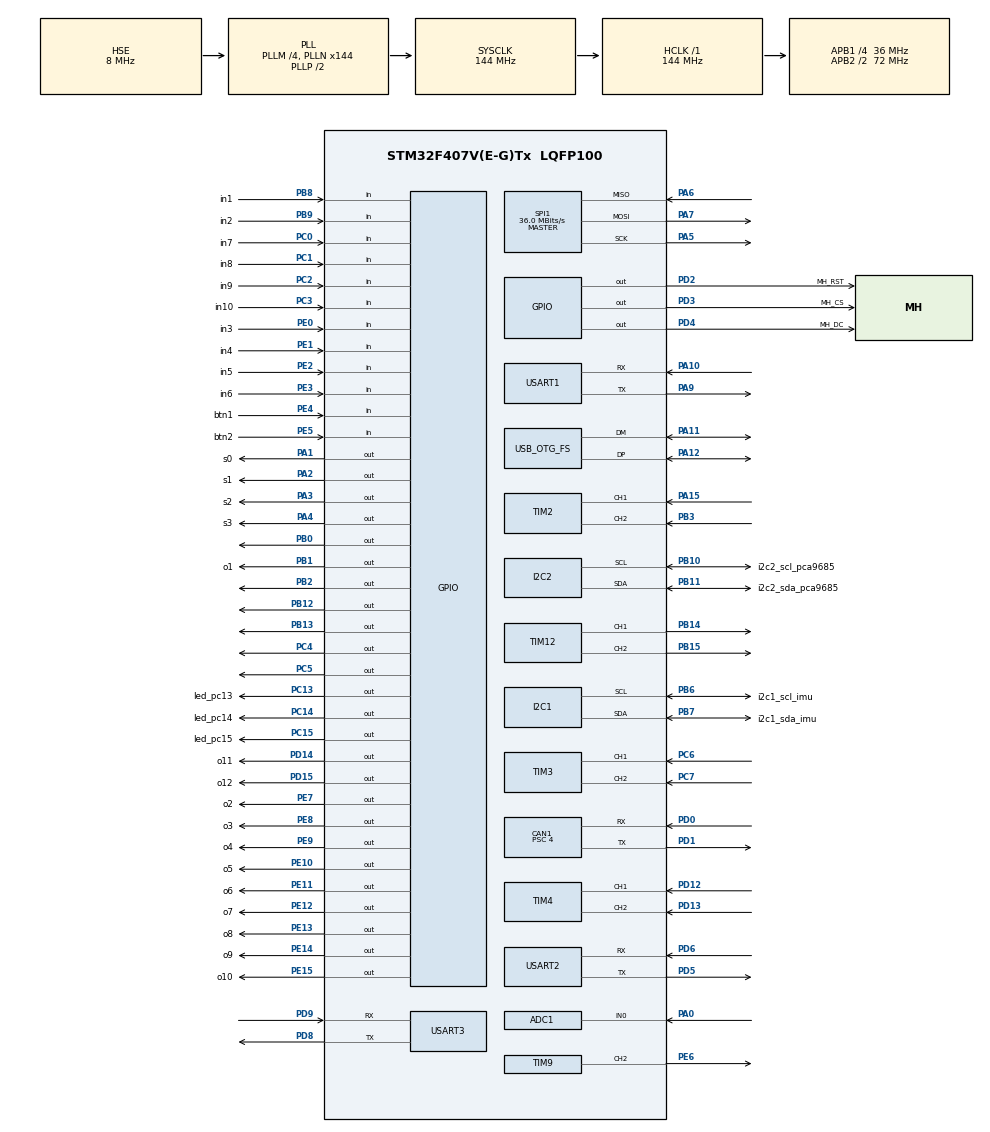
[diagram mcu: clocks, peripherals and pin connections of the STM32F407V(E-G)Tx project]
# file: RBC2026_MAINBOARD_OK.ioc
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ADC1.Channel-0\#ChannelRegularConversion=ADC_CHANNEL_0
ADC1.NbrOfConversionFlag=1
ADC1.Rank-0\#ChannelRegularConversion=1
ADC1.SamplingTime-0\#ChannelRegularConversion=ADC_SAMPLETIME_480CYCLES
ADC1.ScanConvMode=ENABLE
ADC1.master=1
CAN1.ABOM=ENABLE
CAN1.BS1=CAN_BS1_13TQ
CAN1.BS2=CAN_BS2_2TQ
CAN1.CalculateBaudRate=562500
CAN1.CalculateTimeBit=1777
CAN1.CalculateTimeQuantum=111.11111111111111
CAN1.Prescaler=4
Dma.ADC1.0.Direction=DMA_PERIPH_TO_MEMORY
Dma.ADC1.0.FIFOMode=DMA_FIFOMODE_DISABLE
Dma.ADC1.0.Instance=DMA2_Stream0
Dma.ADC1.0.MemDataAlignment=DMA_MDATAALIGN_HALFWORD
Dma.ADC1.0.MemInc=DMA_MINC_ENABLE
Dma.ADC1.0.Mode=DMA_NORMAL
Dma.ADC1.0.PeriphDataAlignment=DMA_PDATAALIGN_HALFWORD
Dma.ADC1.0.PeriphInc=DMA_PINC_DISABLE
Dma.ADC1.0.Priority=DMA_PRIORITY_LOW
Dma.Request0=ADC1
Dma.Request1=USART3_RX
Dma.USART3_RX.1.Direction=DMA_PERIPH_TO_MEMORY
Dma.USART3_RX.1.FIFOMode=DMA_FIFOMODE_DISABLE
Dma.USART3_RX.1.Instance=DMA1_Stream1
Dma.USART3_RX.1.MemDataAlignment=DMA_MDATAALIGN_BYTE
Dma.USART3_RX.1.MemInc=DMA_MINC_ENABLE
Dma.USART3_RX.1.Mode=DMA_NORMAL
Dma.USART3_RX.1.PeriphDataAlignment=DMA_PDATAALIGN_BYTE
Dma.USART3_RX.1.PeriphInc=DMA_PINC_DISABLE
Dma.USART3_RX.1.Priority=DMA_PRIORITY_VERY_HIGH
Mcu.Family=STM32F4
Mcu.Name=STM32F407V(E-G)Tx
Mcu.Package=LQFP100
NVIC.DMA1_Stream1_IRQn=true\:0\:0\:false\:false\:true\:false\:true\:true
NVIC.DMA2_Stream0_IRQn=true\:0\:0\:false\:false\:true\:false\:true\:true
NVIC.OTG_FS_IRQn=true\:0\:0\:false\:false\:true\:false\:true\:true
NVIC.PriorityGroup=NVIC_PRIORITYGROUP_4
NVIC.TIM1_UP_TIM10_IRQn=true\:6\:0\:true\:false\:true\:true\:true\:true
NVIC.TIM8_UP_TIM13_IRQn=true\:7\:0\:true\:false\:true\:true\:true\:true
NVIC.USART3_IRQn=true\:0\:0\:false\:false\:true\:true\:true\:true
PA0-WKUP.Signal=ADCx_IN0
PA1.GPIO_Label=s0
PA1.Signal=GPIO_Output
PA10.Mode=Asynchronous
PA10.Signal=USART1_RX
PA11.Mode=Device_Only
PA11.Signal=USB_OTG_FS_DM
PA12.Mode=Device_Only
PA12.Signal=USB_OTG_FS_DP
PA13.Mode=Serial_Wire
PA13.Signal=SYS_JTMS-SWDIO
PA14.Mode=Serial_Wire
PA14.Signal=SYS_JTCK-SWCLK
PA15.Signal=S_TIM2_CH1_ETR
PA2.GPIO_Label=s1
PA2.Signal=GPIO_Output
PA3.GPIO_Label=s2
PA3.Signal=GPIO_Output
PA4.GPIO_Label=s3
PA4.Signal=GPIO_Output
PA5.Mode=Full_Duplex_Master
PA5.Signal=SPI1_SCK
PA6.Mode=Full_Duplex_Master
PA6.Signal=SPI1_MISO
PA7.Mode=Full_Duplex_Master
PA7.Signal=SPI1_MOSI
PA9.Mode=Asynchronous
PA9.Signal=USART1_TX
PB0.Signal=GPIO_Output
PB1.GPIO_Label=o1
PB1.Signal=GPIO_Output
PB10.GPIO_Label=i2c2_scl_pca9685
PB10.Mode=I2C
PB10.Signal=I2C2_SCL
PB11.GPIO_Label=i2c2_sda_pca9685
PB11.Mode=I2C
PB11.Signal=I2C2_SDA
PB12.Signal=GPIO_Output
PB13.Signal=GPIO_Output
PB14.Signal=S_TIM12_CH1
PB15.Signal=S_TIM12_CH2
PB2.Signal=GPIO_Output
PB3.Signal=S_TIM2_CH2
PB6.GPIO_Label=i2c1_scl_imu
PB6.Mode=I2C
PB6.Signal=I2C1_SCL
PB7.GPIO_Label=i2c1_sda_imu
PB7.Mode=I2C
PB7.Signal=I2C1_SDA
PB8.GPIO_Label=in1
PB8.Signal=GPIO_Input
PB9.GPIO_Label=in2
PB9.Signal=GPIO_Input
PC0.GPIO_Label=in7
PC0.Signal=GPIO_Input
PC1.GPIO_Label=in8
PC1.Signal=GPIO_Input
PC13-ANTI_TAMP.GPIO_Label=led_pc13
PC13-ANTI_TAMP.Signal=GPIO_Output
PC14-OSC32_IN.GPIO_Label=led_pc14
PC14-OSC32_IN.Signal=GPIO_Output
PC15-OSC32_OUT.GPIO_Label=led_pc15
PC15-OSC32_OUT.Signal=GPIO_Output
PC2.GPIO_Label=in9
PC2.Signal=GPIO_Input
PC3.GPIO_Label=in10
PC3.Signal=GPIO_Input
PC4.Signal=GPIO_Output
PC5.Signal=GPIO_Output
PC6.Signal=S_TIM3_CH1
PC7.Signal=S_TIM3_CH2
PD0.Mode=CAN_Activate
PD0.Signal=CAN1_RX
PD1.Mode=CAN_Activate
PD1.Signal=CAN1_TX
PD12.Signal=S_TIM4_CH1
PD13.Signal=S_TIM4_CH2
PD14.GPIO_Label=o11
PD14.Signal=GPIO_Output
PD15.GPIO_Label=o12
PD15.Signal=GPIO_Output
PD2.GPIO_Label=MH_RST
PD2.GPIO_Speed=GPIO_SPEED_FREQ_VERY_HIGH
PD2.Signal=GPIO_Output
PD3.GPIO_Label=MH_CS
PD3.GPIO_Speed=GPIO_SPEED_FREQ_VERY_HIGH
PD3.Signal=GPIO_Output
PD4.GPIO_Label=MH_DC
PD4.GPIO_Speed=GPIO_SPEED_FREQ_VERY_HIGH
PD4.Signal=GPIO_Output
PD5.Mode=Asynchronous
PD5.Signal=USART2_TX
PD6.Mode=Asynchronous
PD6.Signal=USART2_RX
PD8.Mode=Asynchronous
PD8.Signal=USART3_TX
PD9.Mode=Asynchronous
PD9.Signal=USART3_RX
PE0.GPIO_Label=in3
PE0.Signal=GPIO_Input
PE1.GPIO_Label=in4
PE1.Signal=GPIO_Input
PE10.GPIO_Label=o5
PE10.Signal=GPIO_Output
PE11.GPIO_Label=o6
PE11.Signal=GPIO_Output
PE12.GPIO_Label=o7
PE12.Signal=GPIO_Output
PE13.GPIO_Label=o8
PE13.Signal=GPIO_Output
PE14.GPIO_Label=o9
PE14.Signal=GPIO_Output
PE15.GPIO_Label=o10
PE15.Signal=GPIO_Output
PE2.GPIO_Label=in5
PE2.Signal=GPIO_Input
PE3.GPIO_Label=in6
PE3.Signal=GPIO_Input
PE4.GPIO_Label=btn1
PE4.Signal=GPIO_Input
PE5.GPIO_Label=btn2
PE5.Signal=GPIO_Input
PE6.Signal=S_TIM9_CH2
PE7.GPIO_Label=o2
PE7.Signal=GPIO_Output
PE8.GPIO_Label=o3
PE8.Signal=GPIO_Output
PE9.GPIO_Label=o4
PE9.Signal=GPIO_Output
PH0-OSC_IN.Mode=HSE-External-Oscillator
PH0-OSC_IN.Signal=RCC_OSC_IN
PH1-OSC_OUT.Mode=HSE-External-Oscillator
PH1-OSC_OUT.Signal=RCC_OSC_OUT
ProjectManager.HeapSize=0x200
ProjectManager.StackSize=0x400
ProjectManager.TargetToolchain=STM32CubeIDE
RCC.48MHZClocksFreq_Value=48000000
RCC.AHBFreq_Value=144000000
RCC.APB1CLKDivider=RCC_HCLK_DIV4
RCC.APB1Freq_Value=36000000
RCC.APB1TimFreq_Value=72000000
RCC.APB2CLKDivider=RCC_HCLK_DIV2
RCC.APB2Freq_Value=72000000
RCC.APB2TimFreq_Value=144000000
RCC.CortexFreq_Value=144000000
RCC.HCLKFreq_Value=144000000
RCC.HSE_VALUE=8000000
RCC.HSI_VALUE=16000000
RCC.LSE_VALUE=32768
RCC.PLLM=4
RCC.PLLN=144
RCC.PLLQ=6
RCC.SYSCLKFreq_VALUE=144000000
RCC.SYSCLKSource=RCC_SYSCLKSOURCE_PLLCLK
RCC.VCOOutputFreq_Value=288000000
SH.ADCx_IN0.0=ADC1_IN0,IN0
SH.S_TIM12_CH1.0=TIM12_CH1,PWM Generation1 CH1
SH.S_TIM12_CH2.0=TIM12_CH2,PWM Generation2 CH2
SH.S_TIM2_CH1_ETR.0=TIM2_CH1,Encoder_Interface
SH.S_TIM2_CH2.0=TIM2_CH2,Encoder_Interface
SH.S_TIM3_CH1.0=TIM3_CH1,Encoder_Interface
SH.S_TIM3_CH2.0=TIM3_CH2,Encoder_Interface
SH.S_TIM4_CH1.0=TIM4_CH1,Encoder_Interface
SH.S_TIM4_CH2.0=TIM4_CH2,Encoder_Interface
SH.S_TIM9_CH2.0=TIM9_CH2,PWM Generation2 CH2
SPI1.BaudRatePrescaler=SPI_BAUDRATEPRESCALER_2
SPI1.CalculateBaudRate=36.0 MBits/s
SPI1.Direction=SPI_DIRECTION_2LINES
SPI1.Mode=SPI_MODE_MASTER
SPI1.VirtualType=VM_MASTER
TIM1.Period=9999
TIM1.Prescaler=143
TIM12.Channel-PWM\ Generation1\ CH1=TIM_CHANNEL_1
TIM12.Channel-PWM\ Generation2\ CH2=TIM_CHANNEL_2
TIM2.EncoderMode=TIM_ENCODERMODE_TI12
TIM3.EncoderMode=TIM_ENCODERMODE_TI12
TIM4.EncoderMode=TIM_ENCODERMODE_TI12
TIM8.Period=9999
TIM8.Prescaler=2879
TIM9.Channel-PWM\ Generation2\ CH2=TIM_CHANNEL_2
USART1.VirtualMode=VM_ASYNC
USART2.VirtualMode=VM_ASYNC
USART3.VirtualMode=VM_ASYNC
USB_DEVICE.APP_RX_DATA_SIZE-CDC_FS=64
USB_DEVICE.APP_TX_DATA_SIZE-CDC_FS=64
USB_DEVICE.CLASS_NAME_FS=CDC
USB_DEVICE.VirtualMode-CDC_FS=Cdc
USB_DEVICE.VirtualModeFS=Cdc_FS
USB_OTG_FS.VirtualMode=Device_Only
VP_TIM1_VS_ClockSourceINT.Mode=Internal
VP_TIM8_VS_ClockSourceINT.Mode=Internal
VP_USB_DEVICE_VS_USB_DEVICE_CDC_FS.Mode=CDC_FS
board=custom

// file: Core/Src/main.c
/* USER CODE BEGIN Header */
/**
 ******************************************************************************
 * @file           : main.c
 * @brief          : Main program body
 ******************************************************************************
 * @attention
 *
 * Copyright (c) 2025 STMicroelectronics.
 * All rights reserved.
 *
 * This software is licensed under terms that can be found in the LICENSE file
 * in the root directory of this software component.
 * If no LICENSE file comes with this software, it is provided AS-IS.
 *
 ******************************************************************************
 */
/* USER CODE END Header */
#include "main.h"
#include "usb_device.h"

/* USER CODE BEGIN Includes */
#include "ILI9341.h"
#include "bno055.h"
#include "bno055_stm32.h"
#include "math.h"
#include "pca9685.h"
#include "stdio.h"
#include "usbd_cdc_if.h"
/* USER CODE END Includes */

/* USER CODE BEGIN PTD */
bno055_vector_t d;
extern const uint8_t LOGO[];
extern const uint32_t LOGO_size;
extern uint8_t UserRxBufferFS[APP_RX_DATA_SIZE];
extern int current_error_x;
/* USER CODE END PTD */

/* USER CODE BEGIN PD */
#define SERVO_MIN_ANGLE 0
#define SERVO_MAX_ANGLE 180
#define SERVOMIN 125 // ~0.6ms (Góc 0)
#define SERVOMAX 490 // ~2.4ms (Góc 180)

typedef struct {
  float goc_ht[2];
  float goc_trc[2];
  float delta_goc[2];
  float goc_tong[2];
  float goc_offset[2];
  float goc_ok[2];
} IMU;
IMU BNO055 = {};
/* USER CODE END PD */

/* USER CODE BEGIN PM */
uint8_t TxData[8] = {100, 100, 100, 100, 100, 100, 100, 100};
uint8_t TxData2[8] = {100, 100, 100, 100, 100,
                      100, 100, 100}; // Frame 2 cho PID Board 2 (StdId=0x124)
uint32_t TxMailbox;
CAN_TxHeaderTypeDef TxHeader;
CAN_TxHeaderTypeDef TxHeader2; // Header cho frame 2
/* USER CODE END PM */

ADC_HandleTypeDef hadc1;
DMA_HandleTypeDef hdma_adc1;

CAN_HandleTypeDef hcan1;

I2C_HandleTypeDef hi2c1;
I2C_HandleTypeDef hi2c2;

SPI_HandleTypeDef hspi1;

TIM_HandleTypeDef htim1;
TIM_HandleTypeDef htim2;
TIM_HandleTypeDef htim3;
TIM_HandleTypeDef htim4;
TIM_HandleTypeDef htim8;
TIM_HandleTypeDef htim9;
TIM_HandleTypeDef htim12;

UART_HandleTypeDef huart1;
UART_HandleTypeDef huart2;
UART_HandleTypeDef huart3;
DMA_HandleTypeDef hdma_usart3_rx;

/* USER CODE BEGIN PV */
volatile float adc_list[11];
volatile uint8_t channel = 0;
uint32_t adc;
uint8_t check_hc12 = 0;
uint8_t db = 9;
uint8_t pre_check = 0, flag_ok = 0;
float X, Y;
float pii = 3.141592;
float pi4 = 0.7854;
float pi34 = 2.3562;
uint8_t rx_hc12[5] = {};
uint8_t id_hc12;
uint8_t hc12;
uint8_t pre_bt3 = 0;
volatile uint8_t flag_read_imu =
    0; // co hieu: doc IMU an toan ngoai ISR  << moi them
float rad_dh = 0;
float add_rad = 0;
int goc_quay = 0;
float goc_bu = 0;
uint8_t i2c_devices[10];
uint8_t device_count = 0;
/* USER CODE END PV */

void SystemClock_Config(void);
static void MX_GPIO_Init(void);
static void MX_DMA_Init(void);
static void MX_I2C1_Init(void);
static void MX_ADC1_Init(void);
static void MX_I2C2_Init(void);
static void MX_CAN1_Init(void);
static void MX_SPI1_Init(void);
static void MX_TIM2_Init(void);
static void MX_TIM3_Init(void);
static void MX_TIM4_Init(void);
static void MX_TIM9_Init(void);
static void MX_TIM12_Init(void);
static void MX_USART1_UART_Init(void);
static void MX_USART2_UART_Init(void);
static void MX_USART3_UART_Init(void);
static void MX_TIM1_Init(void);
static void MX_TIM8_Init(void);
/* USER CODE BEGIN PFP */
void test_output(void);
/* USER CODE END PFP */

/* USER CODE BEGIN 0 */
// Struct lưu trạng thái (để anh có thể theo dõi trong Debug/Live Watch)
typedef struct {
  uint8_t o1;
  uint8_t o2;
  uint8_t o3;
  uint8_t o4;
  uint8_t o5;
  uint8_t o6;
  uint8_t o7;
  uint8_t o8;
  uint8_t o9;
  uint8_t o10;
  uint8_t o11;
  uint8_t o12;
} OutputState_t;

volatile OutputState_t out_state = {0};

// Cấu hình vật lý (Port, Pin) và con trỏ liên kết đến biến trạng thái ở trên
typedef struct {
  GPIO_TypeDef *port;
  uint16_t pin;
  volatile uint8_t *state;
} DigitalOutput_t;

const DigitalOutput_t outputs[12] = {{o1_GPIO_Port, o1_Pin, &out_state.o1},
                                     {o2_GPIO_Port, o2_Pin, &out_state.o2},
                                     {o3_GPIO_Port, o3_Pin, &out_state.o3},
                                     {o4_GPIO_Port, o4_Pin, &out_state.o4},
                                     {o5_GPIO_Port, o5_Pin, &out_state.o5},
                                     {o6_GPIO_Port, o6_Pin, &out_state.o6},
                                     {o7_GPIO_Port, o7_Pin, &out_state.o7},
                                     {o8_GPIO_Port, o8_Pin, &out_state.o8},
                                     {o9_GPIO_Port, o9_Pin, &out_state.o9},
                                     {o10_GPIO_Port, o10_Pin, &out_state.o10},
                                     {o11_GPIO_Port, o11_Pin, &out_state.o11},
                                     {o12_GPIO_Port, o12_Pin, &out_state.o12}};

void test_output(void) {
  for (int i = 0; i < 12; i++) {
    // Bật output vật lý và cập nhật trạng thái vào struct
    HAL_GPIO_WritePin(outputs[i].port, outputs[i].pin, GPIO_PIN_SET);
    *outputs[i].state = 1;
    HAL_Delay(500);

    // Tắt output vật lý và cập nhật trạng thái
    HAL_GPIO_WritePin(outputs[i].port, outputs[i].pin, GPIO_PIN_RESET);
    *outputs[i].state = 0;
    HAL_Delay(500);
  }
}

void HAL_CAN_TxMailbox0CompleteCallback(CAN_HandleTypeDef *hcan) {
  HAL_GPIO_TogglePin(GPIOC, GPIO_PIN_13);
}

void Update_Display_Data(void) {
  //	if(ready==1){
  //			char buffer[50];
  //			snprintf(buffer, sizeof(buffer), "%d %d %d %d %d %d %d
  //%d %d %d %d",
  // sensor_error[10], sensor_error[9], sensor_error[8],
  // sensor_error[7],
  // sensor_error[6], sensor_error[5],
  // sensor_error[4], sensor_error[3], sensor_error[2],
  // sensor_error[1], sensor_error[0]);
  // ST7735_WriteString(5, 10, buffer, Font_7x10, BLACK, WHITE);
  //
  //			char buff[30];
  //			sprintf(buff, "ER: %-4d", er);
  //			ST7735_WriteString(5, 25, buff, Font_7x10, BLACK,
  // WHITE); 			sprintf(buff, "STATE: %-7s", (robot.sw_start==0)
  // ? "STOP" : "GO!!"); 			ST7735_WriteString(5, 65, buff,
  // Font_7x10, BLACK, WHITE); 			sprintf(buff, "MODE: %-5s",
  // (robot.sw_mode==0) ? "LEARN" : "RUN");
  // ST7735_WriteString(5, 45, buff, Font_7x10, BLACK, WHITE); sprintf(buff,
  // "STEP: %-2d", robot.map_index); ST7735_WriteString(5, 90, buff, Font_7x10,
  // BLACK, WHITE); sprintf(buff, "DIST: %-5ld", robot.sdist);
  ////			sprintf(buff, "IMU: %-4d", goc_z);
  //
  //			ST7735_WriteString(5, 110, buff, Font_7x10, BLACK,
  // WHITE); 			sprintf(buff, "SPM: %d", special_point_mode);
  // ST7735_WriteString(80, 110, buff, Font_7x10, BLACK, WHITE);
  //		}
  //		else{
  //			if (robot.btn_map == BTN_HIGH && robot.pre_btn_map ==
  // BTN_LOW) robot.map=1-robot.map;
  // robot.pre_btn_map=robot.btn_map; 			if (robot.btn_ok ==
  // BTN_HIGH && robot.pre_btn_ok == BTN_LOW) ready=1;
  // ST7735_WriteString(80, 90, robot.map==0 ? "SAN: RED " : "SAN: BLUE",
  // Font_7x10, robot.map==0 ? RED : BLUE, WHITE);
  // ST7735_WriteString(90, 50, "SO_FLY", Font_11x18, robot.map==0
  // ? RED:BLUE, WHITE); 			ST7735_DrawRectangle(0, 0, 160,
  // 40, robot.map==0 ? RED:BLUE); 			ST7735_DrawRectangle(0,
  // 40, 160, 41, robot.map==0 ? RED:BLUE);
  // ST7735_DrawRectangle(0, 81, 160, 47, robot.map==0 ? RED:BLUE);
  //			Select_Robot_Map(robot.map);
  //		}
}
// void Read_IMU(){
//	d = bno055_getVectorEuler();
//	BNO055.goc_ht[0] = d.x;
//	BNO055.delta_goc[0] = BNO055.goc_ht[0] - BNO055.goc_trc[0];
//	if (BNO055.delta_goc[0] > 180) BNO055.delta_goc[0] -= 360;
//	if (BNO055.delta_goc[0] < -180) BNO055.delta_goc[0] += 360;
//	if (BNO055.delta_goc[0] > -1 && BNO055.delta_goc[0] < 1)
// BNO055.delta_goc[0] = 0; // deadband loc nhieu 	BNO055.goc_tong[0] +=
// BNO055.delta_goc[0]; 	BNO055.goc_trc[0] = BNO055.goc_ht[0];
//
//	BNO055.goc_ht[1] = d.z;
//	BNO055.delta_goc[1] = BNO055.goc_ht[1] - BNO055.goc_trc[1];
//	if (BNO055.delta_goc[1] > 180) BNO055.delta_goc[1] -= 360;
//	if (BNO055.delta_goc[1] < -180) BNO055.delta_goc[1] += 360;
//	if (BNO055.delta_goc[1] > -1 && BNO055.delta_goc[1] < 1)
// BNO055.delta_goc[1] = 0; // deadband loc nhieu 	BNO055.goc_tong[1] +=
// BNO055.delta_goc[1]; 	BNO055.goc_trc[1] = BNO055.goc_ht[1];
// }

void Channel(uint8_t channel) {
  HAL_GPIO_WritePin(GPIOA, GPIO_PIN_0,
                    (channel & 0x01) ? GPIO_PIN_SET : GPIO_PIN_RESET); // Bit 0
  HAL_GPIO_WritePin(GPIOA, GPIO_PIN_1,
                    (channel & 0x02) ? GPIO_PIN_SET : GPIO_PIN_RESET); // Bit 1
  HAL_GPIO_WritePin(GPIOA, GPIO_PIN_2,
                    (channel & 0x04) ? GPIO_PIN_SET : GPIO_PIN_RESET); // Bit 2
  HAL_GPIO_WritePin(GPIOA, GPIO_PIN_3,
                    (channel & 0x08) ? GPIO_PIN_SET : GPIO_PIN_RESET); // Bit 3
}
void HAL_ADC_ConvCpltCallback(ADC_HandleTypeDef *hadc) {
  adc_list[channel] = adc;
  channel++;

  if (channel > 3) {
    channel = 0;
  }

  Channel(channel);
  //	for(int i=0;i<300;i++);
  HAL_ADC_Start_DMA(&hadc1, &adc, 1);
}

uint8_t Chuan_hoa(float x) {
  if (x >= 255)
    x = 255;
  if (x <= 0)
    x = 0;
  return (uint8_t)(round(x));
}

void HAL_TIM_PeriodElapsedCallback(TIM_HandleTypeDef *htim) // Doc HC12
{
  if (htim->Instance == TIM8) {

    if (check_hc12 != pre_check) {
      flag_ok = 0;
      HAL_GPIO_TogglePin(GPIOC, GPIO_PIN_13);
    } else {
      flag_ok = 1;
      X = 0;
      Y = 0;
    }
    pre_check = check_hc12;
  }
  if (htim->Instance == TIM1) {
    // Read_MCU();
    // Bug 1 fix: chi bat co, khong goi I2C truc tiep trong ISR
    flag_read_imu = 1;

    if (rx_hc12[2] == 8) {
      //			goc_bu-=0.5;
      // xu li nang ha
      TxData[1] = 150;

    }
    //		else if(rx_hc12[2]==4){
    else if (rx_hc12[2] == 2) {
      //			goc_bu+=0.5;
      // xu li nang ha
      TxData[1] = 50;

    } else {
      TxData[1] = 100;
      //			if(rx_hc12[2]!=pre_bt3){
      if (rx_hc12[2] == 16)
        add_rad = 0;
      else if (rx_hc12[2] == 32)
        add_rad = 2 * pi4; // 2
      else if (rx_hc12[2] == 64)
        add_rad = pii;
      else if (rx_hc12[2] == 128)
        add_rad = -2 * pi4; // 2
      //			}
      // pre_bt3=rx_hc12[4];
      pre_bt3 =
          rx_hc12[2]; // Bug 4 fix: phai luu [2] vi logic tren dung rx_hc12[2]
      rad_dh += (add_rad - rad_dh) * 0.1;
      //			else if(add_rad<rad_dh) rad_dh-=add_rad*0.1;

      goc_quay = BNO055.goc_tong[0] + goc_bu - (int)(rad_dh / pii * 180);

      if (goc_quay > 50)
        goc_quay = 50; // 20
      else if (goc_quay < -50)
        goc_quay = -50; // 20
      float goc_rad = ((goc_quay + BNO055.goc_tong[0] + goc_bu) * pii) / 180;
      //			TxData[2]=Chuan_hoa( X*sin(goc_rad+pi34) +
      // Y*cos(goc_rad+pi34)+100 + goc_quay);
      // TxData[3]=Chuan_hoa( X*sin(goc_rad-pi34) + Y*cos(goc_rad-pi34)+100 +
      // goc_quay); 			TxData[4]=Chuan_hoa(X*sin(goc_rad-pi4) +
      // Y*cos(goc_rad-pi4)+100 + goc_quay);
      //			TxData[5]=Chuan_hoa(X*sin(goc_rad+pi4) +
      // Y*cos(goc_rad+pi4)+100 + goc_quay);

      TxData[2] = Chuan_hoa(X * sin(goc_rad - pi4) + Y * cos(goc_rad - pi4) +
                            100 + goc_quay);
      TxData[3] = Chuan_hoa(X * sin(goc_rad + pi4) + Y * cos(goc_rad + pi4) +
                            100 + goc_quay);
      TxData[4] = Chuan_hoa(X * sin(goc_rad + pi34) + Y * cos(goc_rad + pi34) +
                            100 + goc_quay);
      TxData[5] = Chuan_hoa(X * sin(goc_rad - pi34) + Y * cos(goc_rad - pi34) +
                            100 + goc_quay);
    }
    TxData[6] = db;
    HAL_CAN_AddTxMessage(&hcan1, &TxHeader, TxData, &TxMailbox);

    // Frame 2: gửi dữ liệu cho PID Board 2 (StdId=0x124)
    // TxData2[0-7] - tự thêm chức năng cho các ID chưa sử dụng
    TxData2[6] = db;
    HAL_CAN_AddTxMessage(&hcan1, &TxHeader2, TxData2, &TxMailbox);
  }
}

void I2C1_Scan(void) {
  // Reset mảng và biến đếm trước khi quét
  device_count = 0;
  for (int i = 0; i < 10; i++)
    i2c_devices[i] = 0;

  for (uint16_t i = 1; i < 128; i++) {
    // Kiểm tra thiết bị có phản hồi (ACK) hay không
    // i << 1 vì thư viện HAL sử dụng địa chỉ 8-bit (7-bit address + R/W bit)
    if (HAL_I2C_IsDeviceReady(&hi2c1, (uint16_t)(i << 1), 3, 2) == HAL_OK) {
      if (device_count < 10) {
        i2c_devices[device_count] = (uint8_t)(i << 1);
        device_count++;
      } else {
        // Đã đầy mảng 10 phần tử, dừng quét để bảo vệ bộ nhớ
        break;
      }
    }
  }
}
HAL_StatusTypeDef HC12_Send_AT(char *cmd, char *expected, uint32_t timeout) {
  uint8_t rx_tmp[16];
  uint8_t byte;
  uint8_t idx = 0;
  memset(rx_tmp, 0, sizeof(rx_tmp));

  HAL_UART_Abort(&huart3);
  __HAL_UART_FLUSH_DRREGISTER(&huart3);

  HAL_UART_Transmit(&huart3, (uint8_t *)cmd, strlen(cmd), 100);
  uint32_t start = HAL_GetTick();
  while ((HAL_GetTick() - start) < timeout && idx < 15) {
    if (HAL_UART_Receive(&huart3, &byte, 1, 50) == HAL_OK) {
      rx_tmp[idx++] = byte;

      // Debug: hiện từng byte
      char dbg[32];
      sprintf(dbg, "RX[%d]:%02X '%c'   ", idx - 1, byte,
              (byte >= 32 && byte < 127) ? byte : '.');

      if (strstr((char *)rx_tmp, expected) != NULL) {
        return HAL_OK;
      }
    }
  }
  return HAL_ERROR;
}

void HC12_Setup_Routine(void) {
  uint32_t bauds[] = {9600,  115200, 19200,
                      38400, 4800,   2400}; // ✅ 9600 lên đầu
  uint8_t found = 0;

  for (uint8_t i = 0; i < 6; i++) {
    huart3.Instance = USART3;
    huart3.Init.BaudRate = bauds[i];
    huart3.Init.WordLength = UART_WORDLENGTH_8B;
    huart3.Init.StopBits = UART_STOPBITS_1;
    huart3.Init.Parity = UART_PARITY_NONE;
    huart3.Init.Mode = UART_MODE_TX_RX;
    huart3.Init.HwFlowCtl = UART_HWCONTROL_NONE;
    huart3.Init.OverSampling = UART_OVERSAMPLING_16;
    HAL_UART_Init(&huart3);
    HAL_Delay(50);

    // ✅ Chỉ gửi 1 lần duy nhất qua HC12_Send_AT
    if (HC12_Send_AT("AT\r\n", "OK", 500) == HAL_OK) {
      found = 1;
      char msg[30];
      sprintf(msg, "Found @ %lu", bauds[i]);
      break;
    }
  }

  if (found) {
    HC12_Send_AT("AT+B115200\r\n", "OK", 500);
    HAL_Delay(200); // ✅ Chờ module reboot sau khi đổi baud
    HC12_Send_AT("AT+C059\r\n", "OK", 500);

    huart3.Init.BaudRate = 11520000;
    HAL_UART_Init(&huart3);
  }
}
void HAL_UART_RxCpltCallback(UART_HandleTypeDef *huart) {
  if (huart->Instance == USART3) {
    if (hc12 == 255) {
      id_hc12 = 0;
    } else {
      rx_hc12[id_hc12++] = hc12;
      if (id_hc12 == 5) {
        id_hc12 = 0;
        check_hc12 = rx_hc12[4];
        if (flag_ok == 0) {
          Y = rx_hc12[0] - 100;
          X = -rx_hc12[1] + 100;
        } else {
          X = 0;
          Y = 0;
        }
      }
    }
    HAL_UART_Receive_DMA(&huart3, &hc12, 1);
  }
}

// Servo begin
uint16_t AngleToPWM(uint8_t angle) {
  if (angle > 180)
    angle = 180;
  // Sử dụng tính toán số thực để giữ độ chính xác trước khi ép kiểu
  float pulse =
      (float)SERVOMIN + ((float)angle * (SERVOMAX - SERVOMIN) / 180.0f);
  return (uint16_t)pulse;
}

void SetServoAngle_1(uint8_t num, float angle) {
  uint16_t pwmValue = AngleToPWM(angle);
  PCA9685_SetPWM(&hi2c2, PCA9685_I2C_ADDRESS_1, num, 0, pwmValue);
}

// Servo end

/* USER CODE END 0 */

int main(void) {

  /* MCU Configuration--------------------------------------------------------*/

  /* Reset of all peripherals, Initializes the Flash interface and the Systick.
   */
  HAL_Init();

  /* Configure the system clock */
  SystemClock_Config();

  /* Initialize all configured peripherals */
  MX_GPIO_Init();
  MX_DMA_Init();
  MX_I2C1_Init();
  MX_ADC1_Init();
  MX_I2C2_Init();
  MX_CAN1_Init();
  MX_SPI1_Init();
  MX_TIM2_Init();
  MX_TIM3_Init();
  MX_TIM4_Init();
  MX_TIM9_Init();
  MX_TIM12_Init();
  MX_USART1_UART_Init();
  MX_USART2_UART_Init();
  MX_USART3_UART_Init();
  MX_TIM1_Init();
  MX_TIM8_Init();
  MX_USB_DEVICE_Init();
  /* USER CODE BEGIN 2 */
  ILI9341_Init(&hspi1);
  ILI9341_FillRect(WHITE, 0, 0, 320, 240);
  ILI9341_DrawRect(0, 0, 319, 80, RED);
  ILI9341_DrawRect(0, 80, 319, 80, RED);
  ILI9341_DrawRect(0, 160, 319, 80, RED);

  ILI9341_DrawRect(100, 150, 50, 50, GREEN);
  LCD_PrintString(0, 0, "Do Anh Tuan ke thua Vu Duc Du", BLACK);
  Channel(channel);
  //	HC12_Setup_Routine();
  HAL_ADC_Start_DMA(&hadc1, &adc, 1);
  HAL_Delay(2000);
  //  HAL_CAN_ActivateNotification(&hcan1, CAN_IT_TX_MAILBOX_EMPTY);
  if (HAL_CAN_Start(&hcan1) != HAL_OK) {
    Error_Handler();
  }
  I2C1_Scan();
  HAL_UART_Receive_DMA(&huart3, &hc12, 1);
  bno055_assignI2C(&hi2c1);
  bno055_setup();
  bno055_setOperationModeNDOF();
  PCA9685_Init(&hi2c2, PCA9685_I2C_ADDRESS_1);
  PCA9685_SetPWMFreq(&hi2c2, PCA9685_I2C_ADDRESS_1, 50.0);

  // CAN Frame 1: PID Board 1 (giữ nguyên)
  TxHeader.StdId = 0x123;
  TxHeader.RTR = CAN_RTR_DATA;
  TxHeader.IDE = CAN_ID_STD;
  TxHeader.DLC = 8;
  TxHeader.TransmitGlobalTime = DISABLE;

  // CAN Frame 2: PID Board 2 (thêm mới)
  TxHeader2.StdId = 0x124;
  TxHeader2.RTR = CAN_RTR_DATA;
  TxHeader2.IDE = CAN_ID_STD;
  TxHeader2.DLC = 8;
  TxHeader2.TransmitGlobalTime = DISABLE;
  HAL_TIM_Base_Start_IT(&htim1);
  HAL_TIM_Base_Start_IT(&htim8);
  /* USER CODE END 2 */

  /* Infinite loop */
  while (1) {

    /* USER CODE BEGIN 3 */

    // SetServoAngle_1(0, 90);
    // HAL_Delay(3000);
    // SetServoAngle_1(0, 0);
    // HAL_Delay(3000);
    // Bug 1 fix: Doc IMU an toan ben ngoai ISR

    //  	if(flag_read_imu){
    //  		flag_read_imu = 0;
    //  		Read_IMU();
    //  	}
    test_output();
    // Test servo - xoa khi deploy that
    // SetServoAngle_1(0, 90);
    // HAL_Delay(3000);
    // SetServoAngle_1(0, 0);
    HAL_Delay(100);
  }
  /* USER CODE END 3 */
}

void SystemClock_Config(void) {
  RCC_OscInitTypeDef RCC_OscInitStruct = {0};
  RCC_ClkInitTypeDef RCC_ClkInitStruct = {0};

  /** Configure the main internal regulator output voltage
   */
  __HAL_RCC_PWR_CLK_ENABLE();
  __HAL_PWR_VOLTAGESCALING_CONFIG(PWR_REGULATOR_VOLTAGE_SCALE1);

  /** Initializes the RCC Oscillators according to the specified parameters
   * in the RCC_OscInitTypeDef structure.
   */
  RCC_OscInitStruct.OscillatorType = RCC_OSCILLATORTYPE_HSE;
  RCC_OscInitStruct.HSEState = RCC_HSE_ON;
  RCC_OscInitStruct.PLL.PLLState = RCC_PLL_ON;
  RCC_OscInitStruct.PLL.PLLSource = RCC_PLLSOURCE_HSE;
  RCC_OscInitStruct.PLL.PLLM = 4;
  RCC_OscInitStruct.PLL.PLLN = 144;
  RCC_OscInitStruct.PLL.PLLP = RCC_PLLP_DIV2;
  RCC_OscInitStruct.PLL.PLLQ = 6;
  if (HAL_RCC_OscConfig(&RCC_OscInitStruct) != HAL_OK) {
    Error_Handler();
  }

  /** Initializes the CPU, AHB and APB buses clocks
   */
  RCC_ClkInitStruct.ClockType = RCC_CLOCKTYPE_HCLK | RCC_CLOCKTYPE_SYSCLK |
                                RCC_CLOCKTYPE_PCLK1 | RCC_CLOCKTYPE_PCLK2;
  RCC_ClkInitStruct.SYSCLKSource = RCC_SYSCLKSOURCE_PLLCLK;
  RCC_ClkInitStruct.AHBCLKDivider = RCC_SYSCLK_DIV1;
  RCC_ClkInitStruct.APB1CLKDivider = RCC_HCLK_DIV4;
  RCC_ClkInitStruct.APB2CLKDivider = RCC_HCLK_DIV2;

  if (HAL_RCC_ClockConfig(&RCC_ClkInitStruct, FLASH_LATENCY_4) != HAL_OK) {
    Error_Handler();
  }
}

static void MX_ADC1_Init(void) {

  ADC_ChannelConfTypeDef sConfig = {0};

  /** Configure the global features of the ADC (Clock, Resolution, Data
   * Alignment and number of conversion)
   */
  hadc1.Instance = ADC1;
  hadc1.Init.ClockPrescaler = ADC_CLOCK_SYNC_PCLK_DIV2;
  hadc1.Init.Resolution = ADC_RESOLUTION_12B;
  hadc1.Init.ScanConvMode = ENABLE;
  hadc1.Init.ContinuousConvMode = DISABLE;
  hadc1.Init.DiscontinuousConvMode = DISABLE;
  hadc1.Init.ExternalTrigConvEdge = ADC_EXTERNALTRIGCONVEDGE_NONE;
  hadc1.Init.ExternalTrigConv = ADC_SOFTWARE_START;
  hadc1.Init.DataAlign = ADC_DATAALIGN_RIGHT;
  hadc1.Init.NbrOfConversion = 1;
  hadc1.Init.DMAContinuousRequests = DISABLE;
  hadc1.Init.EOCSelection = ADC_EOC_SINGLE_CONV;
  if (HAL_ADC_Init(&hadc1) != HAL_OK) {
    Error_Handler();
  }

  /** Configure for the selected ADC regular channel its corresponding rank in
   * the sequencer and its sample time.
   */
  sConfig.Channel = ADC_CHANNEL_0;
  sConfig.Rank = 1;
  sConfig.SamplingTime = ADC_SAMPLETIME_480CYCLES;
  if (HAL_ADC_ConfigChannel(&hadc1, &sConfig) != HAL_OK) {
    Error_Handler();
  }
}

static void MX_CAN1_Init(void) {

  hcan1.Instance = CAN1;
  hcan1.Init.Prescaler = 4;
  hcan1.Init.Mode = CAN_MODE_NORMAL;
  hcan1.Init.SyncJumpWidth = CAN_SJW_1TQ;
  hcan1.Init.TimeSeg1 = CAN_BS1_13TQ;
  hcan1.Init.TimeSeg2 = CAN_BS2_2TQ;
  hcan1.Init.TimeTriggeredMode = DISABLE;
  hcan1.Init.AutoBusOff = ENABLE;
  hcan1.Init.AutoWakeUp = DISABLE;
  hcan1.Init.AutoRetransmission = ENABLE;
  hcan1.Init.ReceiveFifoLocked = DISABLE;
  hcan1.Init.TransmitFifoPriority = DISABLE;
  if (HAL_CAN_Init(&hcan1) != HAL_OK) {
    Error_Handler();
  }
}

static void MX_I2C1_Init(void) {

  hi2c1.Instance = I2C1;
  hi2c1.Init.ClockSpeed = 100000;
  hi2c1.Init.DutyCycle = I2C_DUTYCYCLE_2;
  hi2c1.Init.OwnAddress1 = 0;
  hi2c1.Init.AddressingMode = I2C_ADDRESSINGMODE_7BIT;
  hi2c1.Init.DualAddressMode = I2C_DUALADDRESS_DISABLE;
  hi2c1.Init.OwnAddress2 = 0;
  hi2c1.Init.GeneralCallMode = I2C_GENERALCALL_DISABLE;
  hi2c1.Init.NoStretchMode = I2C_NOSTRETCH_DISABLE;
  if (HAL_I2C_Init(&hi2c1) != HAL_OK) {
    Error_Handler();
  }
}

static void MX_I2C2_Init(void) {

  hi2c2.Instance = I2C2;
  hi2c2.Init.ClockSpeed = 100000;
  hi2c2.Init.DutyCycle = I2C_DUTYCYCLE_2;
  hi2c2.Init.OwnAddress1 = 0;
  hi2c2.Init.AddressingMode = I2C_ADDRESSINGMODE_7BIT;
  hi2c2.Init.DualAddressMode = I2C_DUALADDRESS_DISABLE;
  hi2c2.Init.OwnAddress2 = 0;
  hi2c2.Init.GeneralCallMode = I2C_GENERALCALL_DISABLE;
  hi2c2.Init.NoStretchMode = I2C_NOSTRETCH_DISABLE;
  if (HAL_I2C_Init(&hi2c2) != HAL_OK) {
    Error_Handler();
  }
}

static void MX_SPI1_Init(void) {

  /* SPI1 parameter configuration*/
  hspi1.Instance = SPI1;
  hspi1.Init.Mode = SPI_MODE_MASTER;
  hspi1.Init.Direction = SPI_DIRECTION_2LINES;
  hspi1.Init.DataSize = SPI_DATASIZE_8BIT;
  hspi1.Init.CLKPolarity = SPI_POLARITY_LOW;
  hspi1.Init.CLKPhase = SPI_PHASE_1EDGE;
  hspi1.Init.NSS = SPI_NSS_SOFT;
  hspi1.Init.BaudRatePrescaler = SPI_BAUDRATEPRESCALER_2;
  hspi1.Init.FirstBit = SPI_FIRSTBIT_MSB;
  hspi1.Init.TIMode = SPI_TIMODE_DISABLE;
  hspi1.Init.CRCCalculation = SPI_CRCCALCULATION_DISABLE;
  hspi1.Init.CRCPolynomial = 10;
  if (HAL_SPI_Init(&hspi1) != HAL_OK) {
    Error_Handler();
  }
}

static void MX_TIM1_Init(void) {

  TIM_ClockConfigTypeDef sClockSourceConfig = {0};
  TIM_MasterConfigTypeDef sMasterConfig = {0};

  htim1.Instance = TIM1;
  htim1.Init.Prescaler = 143;
  htim1.Init.CounterMode = TIM_COUNTERMODE_UP;
  htim1.Init.Period = 9999;
  htim1.Init.ClockDivision = TIM_CLOCKDIVISION_DIV1;
  htim1.Init.RepetitionCounter = 0;
  htim1.Init.AutoReloadPreload = TIM_AUTORELOAD_PRELOAD_DISABLE;
  if (HAL_TIM_Base_Init(&htim1) != HAL_OK) {
    Error_Handler();
  }
  sClockSourceConfig.ClockSource = TIM_CLOCKSOURCE_INTERNAL;
  if (HAL_TIM_ConfigClockSource(&htim1, &sClockSourceConfig) != HAL_OK) {
    Error_Handler();
  }
  sMasterConfig.MasterOutputTrigger = TIM_TRGO_RESET;
  sMasterConfig.MasterSlaveMode = TIM_MASTERSLAVEMODE_DISABLE;
  if (HAL_TIMEx_MasterConfigSynchronization(&htim1, &sMasterConfig) != HAL_OK) {
    Error_Handler();
  }
}

static void MX_TIM2_Init(void) {

  TIM_Encoder_InitTypeDef sConfig = {0};
  TIM_MasterConfigTypeDef sMasterConfig = {0};

  htim2.Instance = TIM2;
  htim2.Init.Prescaler = 0;
  htim2.Init.CounterMode = TIM_COUNTERMODE_UP;
  htim2.Init.Period = 4294967295;
  htim2.Init.ClockDivision = TIM_CLOCKDIVISION_DIV1;
  htim2.Init.AutoReloadPreload = TIM_AUTORELOAD_PRELOAD_DISABLE;
  sConfig.EncoderMode = TIM_ENCODERMODE_TI12;
  sConfig.IC1Polarity = TIM_ICPOLARITY_RISING;
  sConfig.IC1Selection = TIM_ICSELECTION_DIRECTTI;
  sConfig.IC1Prescaler = TIM_ICPSC_DIV1;
  sConfig.IC1Filter = 0;
  sConfig.IC2Polarity = TIM_ICPOLARITY_RISING;
  sConfig.IC2Selection = TIM_ICSELECTION_DIRECTTI;
  sConfig.IC2Prescaler = TIM_ICPSC_DIV1;
  sConfig.IC2Filter = 0;
  if (HAL_TIM_Encoder_Init(&htim2, &sConfig) != HAL_OK) {
    Error_Handler();
  }
  sMasterConfig.MasterOutputTrigger = TIM_TRGO_RESET;
  sMasterConfig.MasterSlaveMode = TIM_MASTERSLAVEMODE_DISABLE;
  if (HAL_TIMEx_MasterConfigSynchronization(&htim2, &sMasterConfig) != HAL_OK) {
    Error_Handler();
  }
}

static void MX_TIM3_Init(void) {

  TIM_Encoder_InitTypeDef sConfig = {0};
  TIM_MasterConfigTypeDef sMasterConfig = {0};

  htim3.Instance = TIM3;
  htim3.Init.Prescaler = 0;
  htim3.Init.CounterMode = TIM_COUNTERMODE_UP;
  htim3.Init.Period = 65535;
  htim3.Init.ClockDivision = TIM_CLOCKDIVISION_DIV1;
  htim3.Init.AutoReloadPreload = TIM_AUTORELOAD_PRELOAD_DISABLE;
  sConfig.EncoderMode = TIM_ENCODERMODE_TI12;
  sConfig.IC1Polarity = TIM_ICPOLARITY_RISING;
  sConfig.IC1Selection = TIM_ICSELECTION_DIRECTTI;
  sConfig.IC1Prescaler = TIM_ICPSC_DIV1;
  sConfig.IC1Filter = 0;
  sConfig.IC2Polarity = TIM_ICPOLARITY_RISING;
  sConfig.IC2Selection = TIM_ICSELECTION_DIRECTTI;
  sConfig.IC2Prescaler = TIM_ICPSC_DIV1;
  sConfig.IC2Filter = 0;
  if (HAL_TIM_Encoder_Init(&htim3, &sConfig) != HAL_OK) {
    Error_Handler();
  }
  sMasterConfig.MasterOutputTrigger = TIM_TRGO_RESET;
  sMasterConfig.MasterSlaveMode = TIM_MASTERSLAVEMODE_DISABLE;
  if (HAL_TIMEx_MasterConfigSynchronization(&htim3, &sMasterConfig) != HAL_OK) {
    Error_Handler();
  }
}

static void MX_TIM4_Init(void) {

  TIM_Encoder_InitTypeDef sConfig = {0};
  TIM_MasterConfigTypeDef sMasterConfig = {0};

  htim4.Instance = TIM4;
  htim4.Init.Prescaler = 0;
  htim4.Init.CounterMode = TIM_COUNTERMODE_UP;
  htim4.Init.Period = 65535;
  htim4.Init.ClockDivision = TIM_CLOCKDIVISION_DIV1;
  htim4.Init.AutoReloadPreload = TIM_AUTORELOAD_PRELOAD_DISABLE;
  sConfig.EncoderMode = TIM_ENCODERMODE_TI12;
  sConfig.IC1Polarity = TIM_ICPOLARITY_RISING;
  sConfig.IC1Selection = TIM_ICSELECTION_DIRECTTI;
  sConfig.IC1Prescaler = TIM_ICPSC_DIV1;
  sConfig.IC1Filter = 0;
  sConfig.IC2Polarity = TIM_ICPOLARITY_RISING;
  sConfig.IC2Selection = TIM_ICSELECTION_DIRECTTI;
  sConfig.IC2Prescaler = TIM_ICPSC_DIV1;
  sConfig.IC2Filter = 0;
  if (HAL_TIM_Encoder_Init(&htim4, &sConfig) != HAL_OK) {
    Error_Handler();
  }
  sMasterConfig.MasterOutputTrigger = TIM_TRGO_RESET;
  sMasterConfig.MasterSlaveMode = TIM_MASTERSLAVEMODE_DISABLE;
  if (HAL_TIMEx_MasterConfigSynchronization(&htim4, &sMasterConfig) != HAL_OK) {
    Error_Handler();
  }
}

static void MX_TIM8_Init(void) {

  TIM_ClockConfigTypeDef sClockSourceConfig = {0};
  TIM_MasterConfigTypeDef sMasterConfig = {0};

  htim8.Instance = TIM8;
  htim8.Init.Prescaler = 2879;
  htim8.Init.CounterMode = TIM_COUNTERMODE_UP;
  htim8.Init.Period = 9999;
  htim8.Init.ClockDivision = TIM_CLOCKDIVISION_DIV1;
  htim8.Init.RepetitionCounter = 0;
  htim8.Init.AutoReloadPreload = TIM_AUTORELOAD_PRELOAD_DISABLE;
  if (HAL_TIM_Base_Init(&htim8) != HAL_OK) {
    Error_Handler();
  }
  sClockSourceConfig.ClockSource = TIM_CLOCKSOURCE_INTERNAL;
  if (HAL_TIM_ConfigClockSource(&htim8, &sClockSourceConfig) != HAL_OK) {
    Error_Handler();
  }
  sMasterConfig.MasterOutputTrigger = TIM_TRGO_RESET;
  sMasterConfig.MasterSlaveMode = TIM_MASTERSLAVEMODE_DISABLE;
  if (HAL_TIMEx_MasterConfigSynchronization(&htim8, &sMasterConfig) != HAL_OK) {
    Error_Handler();
  }
}

static void MX_TIM9_Init(void) {

  TIM_OC_InitTypeDef sConfigOC = {0};

  htim9.Instance = TIM9;
  htim9.Init.Prescaler = 0;
  htim9.Init.CounterMode = TIM_COUNTERMODE_UP;
  htim9.Init.Period = 65535;
  htim9.Init.ClockDivision = TIM_CLOCKDIVISION_DIV1;
  htim9.Init.AutoReloadPreload = TIM_AUTORELOAD_PRELOAD_DISABLE;
  if (HAL_TIM_PWM_Init(&htim9) != HAL_OK) {
    Error_Handler();
  }
  sConfigOC.OCMode = TIM_OCMODE_PWM1;
  sConfigOC.Pulse = 0;
  sConfigOC.OCPolarity = TIM_OCPOLARITY_HIGH;
  sConfigOC.OCFastMode = TIM_OCFAST_DISABLE;
  if (HAL_TIM_PWM_ConfigChannel(&htim9, &sConfigOC, TIM_CHANNEL_2) != HAL_OK) {
    Error_Handler();
  }
  HAL_TIM_MspPostInit(&htim9);
}

static void MX_TIM12_Init(void) {

  TIM_OC_InitTypeDef sConfigOC = {0};

  htim12.Instance = TIM12;
  htim12.Init.Prescaler = 0;
  htim12.Init.CounterMode = TIM_COUNTERMODE_UP;
  htim12.Init.Period = 65535;
  htim12.Init.ClockDivision = TIM_CLOCKDIVISION_DIV1;
  htim12.Init.AutoReloadPreload = TIM_AUTORELOAD_PRELOAD_DISABLE;
  if (HAL_TIM_PWM_Init(&htim12) != HAL_OK) {
    Error_Handler();
  }
  sConfigOC.OCMode = TIM_OCMODE_PWM1;
  sConfigOC.Pulse = 0;
  sConfigOC.OCPolarity = TIM_OCPOLARITY_HIGH;
  sConfigOC.OCFastMode = TIM_OCFAST_DISABLE;
  if (HAL_TIM_PWM_ConfigChannel(&htim12, &sConfigOC, TIM_CHANNEL_1) != HAL_OK) {
    Error_Handler();
  }
  if (HAL_TIM_PWM_ConfigChannel(&htim12, &sConfigOC, TIM_CHANNEL_2) != HAL_OK) {
    Error_Handler();
  }
  HAL_TIM_MspPostInit(&htim12);
}

static void MX_USART1_UART_Init(void) {

  huart1.Instance = USART1;
  huart1.Init.BaudRate = 115200;
  huart1.Init.WordLength = UART_WORDLENGTH_8B;
  huart1.Init.StopBits = UART_STOPBITS_1;
  huart1.Init.Parity = UART_PARITY_NONE;
  huart1.Init.Mode = UART_MODE_TX_RX;
  huart1.Init.HwFlowCtl = UART_HWCONTROL_NONE;
  huart1.Init.OverSampling = UART_OVERSAMPLING_16;
  if (HAL_UART_Init(&huart1) != HAL_OK) {
    Error_Handler();
  }
}

static void MX_USART2_UART_Init(void) {

  huart2.Instance = USART2;
  huart2.Init.BaudRate = 115200;
  huart2.Init.WordLength = UART_WORDLENGTH_8B;
  huart2.Init.StopBits = UART_STOPBITS_1;
  huart2.Init.Parity = UART_PARITY_NONE;
  huart2.Init.Mode = UART_MODE_TX_RX;
  huart2.Init.HwFlowCtl = UART_HWCONTROL_NONE;
  huart2.Init.OverSampling = UART_OVERSAMPLING_16;
  if (HAL_UART_Init(&huart2) != HAL_OK) {
    Error_Handler();
  }
}

static void MX_USART3_UART_Init(void) {

  huart3.Instance = USART3;
  huart3.Init.BaudRate = 115200;
  huart3.Init.WordLength = UART_WORDLENGTH_8B;
  huart3.Init.StopBits = UART_STOPBITS_1;
  huart3.Init.Parity = UART_PARITY_NONE;
  huart3.Init.Mode = UART_MODE_TX_RX;
  huart3.Init.HwFlowCtl = UART_HWCONTROL_NONE;
  huart3.Init.OverSampling = UART_OVERSAMPLING_16;
  if (HAL_UART_Init(&huart3) != HAL_OK) {
    Error_Handler();
  }
}

static void MX_DMA_Init(void) {

  /* DMA controller clock enable */
  __HAL_RCC_DMA2_CLK_ENABLE();
  __HAL_RCC_DMA1_CLK_ENABLE();

  /* DMA interrupt init */
  /* DMA1_Stream1_IRQn interrupt configuration */
  HAL_NVIC_SetPriority(DMA1_Stream1_IRQn, 0, 0);
  HAL_NVIC_EnableIRQ(DMA1_Stream1_IRQn);
  /* DMA2_Stream0_IRQn interrupt configuration */
  HAL_NVIC_SetPriority(DMA2_Stream0_IRQn, 0, 0);
  HAL_NVIC_EnableIRQ(DMA2_Stream0_IRQn);
}

static void MX_GPIO_Init(void) {
  GPIO_InitTypeDef GPIO_InitStruct = {0};

  /* GPIO Ports Clock Enable */
  __HAL_RCC_GPIOE_CLK_ENABLE();
  __HAL_RCC_GPIOC_CLK_ENABLE();
  __HAL_RCC_GPIOH_CLK_ENABLE();
  __HAL_RCC_GPIOA_CLK_ENABLE();
  __HAL_RCC_GPIOB_CLK_ENABLE();
  __HAL_RCC_GPIOD_CLK_ENABLE();

  /*Configure GPIO pin Output Level */
  HAL_GPIO_WritePin(GPIOC,
                    led_pc13_Pin | led_pc14_Pin | led_pc15_Pin | GPIO_PIN_4 |
                        GPIO_PIN_5,
                    GPIO_PIN_RESET);

  /*Configure GPIO pin Output Level */
  HAL_GPIO_WritePin(GPIOA, s0_Pin | s1_Pin | s2_Pin | s3_Pin, GPIO_PIN_RESET);

  /*Configure GPIO pin Output Level */
  HAL_GPIO_WritePin(
      GPIOB, GPIO_PIN_0 | o1_Pin | GPIO_PIN_2 | GPIO_PIN_12 | GPIO_PIN_13,
      GPIO_PIN_RESET);

  /*Configure GPIO pin Output Level */
  HAL_GPIO_WritePin(GPIOE,
                    o2_Pin | o3_Pin | o4_Pin | o5_Pin | o6_Pin | o7_Pin |
                        o8_Pin | o9_Pin | o10_Pin,
                    GPIO_PIN_RESET);

  /*Configure GPIO pin Output Level */
  HAL_GPIO_WritePin(GPIOD,
                    o11_Pin | o12_Pin | MH_RST_Pin | MH_CS_Pin | MH_DC_Pin,
                    GPIO_PIN_RESET);

  /*Configure GPIO pins : in5_Pin in6_Pin btn1_Pin btn2_Pin
                           in3_Pin in4_Pin */
  GPIO_InitStruct.Pin =
      in5_Pin | in6_Pin | btn1_Pin | btn2_Pin | in3_Pin | in4_Pin;
  GPIO_InitStruct.Mode = GPIO_MODE_INPUT;
  GPIO_InitStruct.Pull = GPIO_NOPULL;
  HAL_GPIO_Init(GPIOE, &GPIO_InitStruct);

  /*Configure GPIO pins : led_pc13_Pin led_pc14_Pin led_pc15_Pin PC4
                           PC5 */
  GPIO_InitStruct.Pin =
      led_pc13_Pin | led_pc14_Pin | led_pc15_Pin | GPIO_PIN_4 | GPIO_PIN_5;
  GPIO_InitStruct.Mode = GPIO_MODE_OUTPUT_PP;
  GPIO_InitStruct.Pull = GPIO_NOPULL;
  GPIO_InitStruct.Speed = GPIO_SPEED_FREQ_LOW;
  HAL_GPIO_Init(GPIOC, &GPIO_InitStruct);

  /*Configure GPIO pins : in7_Pin in8_Pin in9_Pin in10_Pin */
  GPIO_InitStruct.Pin = in7_Pin | in8_Pin | in9_Pin | in10_Pin;
  GPIO_InitStruct.Mode = GPIO_MODE_INPUT;
  GPIO_InitStruct.Pull = GPIO_NOPULL;
  HAL_GPIO_Init(GPIOC, &GPIO_InitStruct);

  /*Configure GPIO pins : s0_Pin s1_Pin s2_Pin s3_Pin */
  GPIO_InitStruct.Pin = s0_Pin | s1_Pin | s2_Pin | s3_Pin;
  GPIO_InitStruct.Mode = GPIO_MODE_OUTPUT_PP;
  GPIO_InitStruct.Pull = GPIO_NOPULL;
  GPIO_InitStruct.Speed = GPIO_SPEED_FREQ_LOW;
  HAL_GPIO_Init(GPIOA, &GPIO_InitStruct);

  /*Configure GPIO pins : PB0 o1_Pin PB2 PB12
                           PB13 */
  GPIO_InitStruct.Pin =
      GPIO_PIN_0 | o1_Pin | GPIO_PIN_2 | GPIO_PIN_12 | GPIO_PIN_13;
  GPIO_InitStruct.Mode = GPIO_MODE_OUTPUT_PP;
  GPIO_InitStruct.Pull = GPIO_NOPULL;
  GPIO_InitStruct.Speed = GPIO_SPEED_FREQ_LOW;
  HAL_GPIO_Init(GPIOB, &GPIO_InitStruct);

  /*Configure GPIO pins : o2_Pin o3_Pin o4_Pin o5_Pin
                           o6_Pin o7_Pin o8_Pin o9_Pin
                           o10_Pin */
  GPIO_InitStruct.Pin = o2_Pin | o3_Pin | o4_Pin | o5_Pin | o6_Pin | o7_Pin |
                        o8_Pin | o9_Pin | o10_Pin;
  GPIO_InitStruct.Mode = GPIO_MODE_OUTPUT_PP;
  GPIO_InitStruct.Pull = GPIO_NOPULL;
  GPIO_InitStruct.Speed = GPIO_SPEED_FREQ_LOW;
  HAL_GPIO_Init(GPIOE, &GPIO_InitStruct);

  /*Configure GPIO pins : o11_Pin o12_Pin */
  GPIO_InitStruct.Pin = o11_Pin | o12_Pin;
  GPIO_InitStruct.Mode = GPIO_MODE_OUTPUT_PP;
  GPIO_InitStruct.Pull = GPIO_NOPULL;
  GPIO_InitStruct.Speed = GPIO_SPEED_FREQ_LOW;
  HAL_GPIO_Init(GPIOD, &GPIO_InitStruct);

  /*Configure GPIO pins : MH_RST_Pin MH_CS_Pin MH_DC_Pin */
  GPIO_InitStruct.Pin = MH_RST_Pin | MH_CS_Pin | MH_DC_Pin;
  GPIO_InitStruct.Mode = GPIO_MODE_OUTPUT_PP;
  GPIO_InitStruct.Pull = GPIO_NOPULL;
  GPIO_InitStruct.Speed = GPIO_SPEED_FREQ_VERY_HIGH;
  HAL_GPIO_Init(GPIOD, &GPIO_InitStruct);

  /*Configure GPIO pins : in1_Pin in2_Pin */
  GPIO_InitStruct.Pin = in1_Pin | in2_Pin;
  GPIO_InitStruct.Mode = GPIO_MODE_INPUT;
  GPIO_InitStruct.Pull = GPIO_NOPULL;
  HAL_GPIO_Init(GPIOB, &GPIO_InitStruct);

}

/* USER CODE BEGIN 4 */
/* USER CODE BEGIN 4 */
void HAL_UART_ErrorCallback(UART_HandleTypeDef *huart) {
  if (huart->Instance == USART3) {
    uint32_t isrflags = READ_REG(huart->Instance->SR); // Với dòng F4 dùng SR
    if ((isrflags & UART_FLAG_ORE) != RESET) {
      __HAL_UART_CLEAR_OREFLAG(huart);
    }
    if ((isrflags & UART_FLAG_FE) != RESET) {
      __HAL_UART_CLEAR_FEFLAG(huart);
    }

    // Quan trọng: Phải khởi động lại DMA sau khi lỗi
    HAL_UART_Receive_DMA(&huart3, &hc12, 1);
  }
}
/* USER CODE END 4 */

void Error_Handler(void) {
  __disable_irq();
  while (1) {
  }
}
#ifdef USE_FULL_ASSERT
/**
 * @brief  Reports the name of the source file and the source line number
 *         where the assert_param error has occurred.
 * @param  file: pointer to the source file name
 * @param  line: assert_param error line source number
 * @retval None
 */
void assert_failed(uint8_t *file, uint32_t line) {
  /* USER CODE BEGIN 6 */
  /* User can add his own implementation to report the file name and line
     number, ex: printf("Wrong parameters value: file %s on line %d\r\n", file,
     line) */
  /* USER CODE END 6 */
}
#endif /* USE_FULL_ASSERT */
